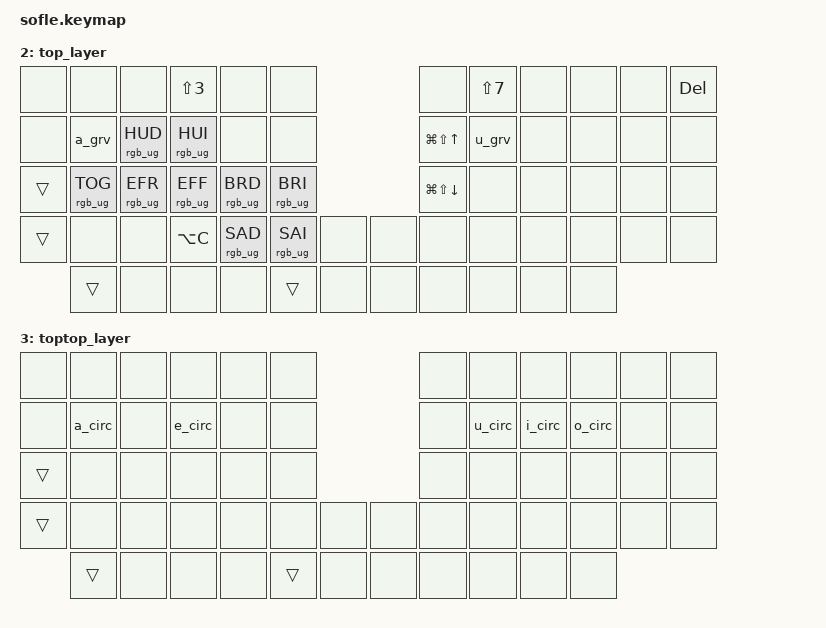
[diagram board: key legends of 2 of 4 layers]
/*
 * Copyright (c) 2020 The ZMK Contributors
 *
 * SPDX-License-Identifier: MIT
 */

#include <behaviors.dtsi>
#include <dt-bindings/zmk/keys.h>
#include <dt-bindings/zmk/bt.h>
#include <dt-bindings/zmk/ext_power.h>
#include <dt-bindings/zmk/rgb.h>


/ {

    chosen {
      zmk,battery = &vbatt;
    };

    vbatt: vbatt {
        compatible = "zmk,battery-nrf-vddh";
        label = "VBATT";
    };
    

    
    macros {
    
    layer_s: layer_s {
	    label = "layer shift color";
	    compatible = "zmk,behavior-macro";
	    #binding-cells = <0>;
	    wait-ms = <0>;
	    tap-ms = <0>;
	    bindings
		= <&macro_press &kp LSHFT>
		, <&macro_tap &rgb_ug RGB_COLOR_HSB(35,100,4)>
		, <&macro_pause_for_release>
		, <&macro_release &kp LSHFT>
		, <&macro_tap &rgb_ug RGB_COLOR_HSB(240,0,1)>
		;
	};
    

    layer_a: layer_a {
	    label = "layer a";
	    compatible = "zmk,behavior-macro";
	    #binding-cells = <0>;
	    wait-ms = <0>;
	    tap-ms = <0>;
	    bindings
		= <&macro_press &mo 1>
		, <&macro_tap &rgb_ug RGB_COLOR_HSB(300,100,4)>
		, <&macro_pause_for_release>
		, <&macro_release &mo 1>
		, <&macro_tap &rgb_ug RGB_COLOR_HSB(240,0,1)>
		;
	};
	
	layer_b: layer_b {
	    label = "layer b";
	    compatible = "zmk,behavior-macro";
	    #binding-cells = <0>;
	    wait-ms = <0>;
	    tap-ms = <0>;
	    bindings
		= <&macro_press &mo 2>
		, <&macro_tap &rgb_ug RGB_COLOR_HSB(175,100,4)>
		, <&macro_pause_for_release>
		, <&macro_release &mo 2>
		, <&macro_tap &rgb_ug RGB_COLOR_HSB(240,0,1)>
		;
	};
	
	layer_c: layer_c {
	    label = "layer c";
	    compatible = "zmk,behavior-macro";
	    #binding-cells = <0>;
	    wait-ms = <0>;
	    tap-ms = <0>;
	    bindings
		= <&macro_press &sl 3>
		, <&macro_tap &rgb_ug RGB_COLOR_HSB(0,100,4)>
		, <&macro_pause_for_release>
		, <&macro_release &sl 3>
		;
	};

        e_aig: e_aig {
            label = "e aigu";
	    tap-ms = <50>;
            compatible = "zmk,behavior-macro";
            #binding-cells = <0>;
            bindings
                = <&macro_tap &kp LA(E)>
                , <&macro_tap &kp E>
                ;
        };
	
	a_grv: a_grv {
            label = "a grave";
	    tap-ms = <50>;
            compatible = "zmk,behavior-macro";
            #binding-cells = <0>;
            bindings
                = <&macro_tap &kp LA(GRAVE)>
                , <&macro_tap &kp A>
                ;
        };
	
	a_circ: a_circ {
            label = "a circ";
	    tap-ms = <50>;
            compatible = "zmk,behavior-macro";
            #binding-cells = <0>;
            bindings
                = <&macro_tap &kp LA(I)>
                , <&macro_tap &kp A>
                ;
        };
	
	e_grv: e_grv {
            label = "e grave";
	    tap-ms = <50>;
            compatible = "zmk,behavior-macro";
            #binding-cells = <0>;
            bindings
                = <&macro_tap &kp LA(GRAVE)>
                , <&macro_tap &kp E>
                ;
        };
	
	e_circ: e_circ {
            label = "e circ";
	    tap-ms = <50>;
            compatible = "zmk,behavior-macro";
            #binding-cells = <0>;
            bindings
                = <&macro_tap &kp LA(I)>
                , <&macro_tap &kp E>
                ;
        };
	
	u_grv: u_grv {
            label = "u grave";
	    tap-ms = <50>;
            compatible = "zmk,behavior-macro";
            #binding-cells = <0>;
            bindings
                = <&macro_tap &kp LA(GRAVE)>
                , <&macro_tap &kp U>
                ;
        };
	
	u_circ: u_circ {
            label = "u circ";
	    tap-ms = <50>;
            compatible = "zmk,behavior-macro";
            #binding-cells = <0>;
            bindings
                = <&macro_tap &kp LA(I)>
                , <&macro_tap &kp U>
                ;
        };
	
	o_circ: o_circ {
            label = "o circ";
	    tap-ms = <50>;
            compatible = "zmk,behavior-macro";
            #binding-cells = <0>;
            bindings
                = <&macro_tap &kp LA(I)>
                , <&macro_tap &kp O>
                ;
        };
	
	i_circ: i_circ {
            label = "i circ";
	    tap-ms = <50>;
            compatible = "zmk,behavior-macro";
            #binding-cells = <0>;
            bindings
                = <&macro_tap &kp LA(I)>
                , <&macro_tap &kp I>
                ;
        };

    };

    behaviors {
        hm: homerow_mods {
            compatible = "zmk,behavior-hold-tap";
            label = "HOMEROW_MODS";
            #binding-cells = <2>;
            tapping-term-ms = <150>;
            quick-tap-ms = <0>;
            flavor = "tap-preferred";
            bindings = <&kp>, <&kp>;
        };

	aa: aa {
            compatible = "zmk,behavior-tap-dance";
            label = "select all";
            #binding-cells = <0>;
            tapping-term-ms = <100>;
            bindings = <&kp A>, <&kp LG(A)>;
        };

        cc: cc {
            compatible = "zmk,behavior-tap-dance";
            label = "copy";
            #binding-cells = <0>;
            tapping-term-ms = <100>;
            bindings = <&kp C>, <&kp LG(C)>;
        };

        cv: cv {
            compatible = "zmk,behavior-tap-dance";
            label = "paste";
            #binding-cells = <0>;
            tapping-term-ms = <100>;
            bindings = <&kp V>, <&kp LG(V)>;
        };

        cx: cx {
            compatible = "zmk,behavior-tap-dance";
            label = "cut";
            #binding-cells = <0>;
            tapping-term-ms = <100>;
            bindings = <&kp X>, <&kp LG(X)>;
        };
	
    };

	keymap {
		compatible = "zmk,keymap";

		default_layer {
// ------------------------------------------------------------------------------------------------------------
// |  ESC  |  1 ou !  | 2 ou é  | 3 ou #   | 4 ou $   | 5 ou %   |                 | 6 ou ^   | 7 ou é    | 8 ou *    | 9 ou (   |  0 ou )   | BACKSPACE |
// |  TAB  |  A       |  Z      |  E       |  R       |  T       |                 |  Y       |  U        |  I        |  O       |   P       |   + ou =  |
// |  CTRL |  Q       |  S      |  D       |  F       |  G       |                 |  H       |  J        |  K        |  L       |   M       |   ' ou "  |
// |  CMD  |  W       |  X      |  C       |  V       |  B       |  L/R  | | U/D   |  N       | ; ou :    |  , ou <   | . ou >   |   / ou ?  |  RIGHT    |
//                    | ALT     | [ ou {   | LOWER    |  SHIFT   | ENTER | | SPACE | UPPER    | - ou _    | }         |   LEFT   |
			bindings = <
    &kp ESC   &kp LS(N1) &e_aig      &kp LS(N3)        &kp LS(N4) &kp LS(N5)                        &kp LS(N6) &e_grv     &kp LS(N8)        &kp LS(N9)    &kp LS(N0)      &kp BSPC
    &kp TAB   &kp A      &kp Z       &kp E             &kp R      &kp T                             &kp Y      &kp U      &kp I             &kp O         &kp P           &kp EQUAL
    &kp LCTRL &kp Q      &kp S       &kp D             &kp F      &kp G                             &kp H      &kp J      &kp K             &kp L         &kp M           &kp SQT
    &kp LCMD  &kp W      &kp X       &kp C             &kp V      &kp B       &none     &none       &kp N      &kp SEMI   &kp COMMA         &kp DOT       &kp SLASH       &kp RIGHT
                         &kp LALT    &kp LBKT          &layer_a   &layer_s    &kp ENTER &kp SPACE   &layer_b   &kp MINUS  &kp RBKT          &kp LEFT
			>;
			
			sensor-bindings = <&inc_dec_kp LEFT RIGHT &inc_dec_kp DOWN UP>;

		};

		lower_layer {
// ------------------------------------------------------------------------------------------------------------
// | ESC    |  1  |   2    |   3     |  `     |  [          |                   |  F6        |  F7   |  F8              |   F9        |  F10      |  ]        |
// | BT_NXT | @   |        |         | rename |             |                   |            |  UP   | chrome dev tools | format code | = et +    | - et _    |
// |        |     |        |         |  find  | multi caret |                   | LEFT       | DOWN  |  RIGHT           |  "|"        | x meth    | $ et *    |
// |        |     | x meth | x const | x var  | x field     |        |  | del   | open class |       |                  |  \          |   line up | line down |
//                |        |    [    |        |             |        |  |       |            | ]     |            HOME  |  END        |
			bindings = <
&kp ESC              &kp N1             &kp N2          &kp N3              &kp N4          &kp N5                                        &kp N6      &kp N7           &kp N8           &kp N9           &kp N0           &kp DELETE
&bt BT_NXT           &kp LS(N2)         &none           &none               &kp LS(F6)      &none                                         &kp UP      &u_grv           &kp LA(LG(I))    &kp LA(LG(L))    &none            &trans
&trans               &none              &none           &none               &kp LC(LS(F))   &kp LC(LG(G))                                 &kp DOWN    &none            &none            &kp PIPE         &kp LA(LG(M))    &kp GRAVE
&trans               &none              &kp LA(LG(M))   &kp LA(LG(C))       &kp LA(LG(V))   &kp LA(LG(F))    &none         &none          &kp LG(N)   &none            &trans           &trans           &kp BACKSLASH    &kp TILDE
                                        &trans          &bt BT_CLR          &none           &trans            &kp LG(LEFT)  &kp LG(RIGHT)  &layer_c    &trans           &none            &none         
			>;

			sensor-bindings = <&inc_dec_kp BSPC DEL &inc_dec_kp PG_UP PG_DN>;
		};

        top_layer {
        // ------------------------------------------------------------------------------------------------------------
        // |       |F1   |  F2 |  F3  |  F4  |  F5   |                   |      |       |       |      |       |       |
        // |  >    |     |     |      |      |       |                   |      |       |       |      |       |       |
        // |       |     |     |      |      |       |                   |      |       |       |      |       |       |
        // |       |     |     |      |      |       |        |  |   <   |      |       |       |      |       |       |
        //               |     |      |      |       |        |  |       |      |       |       |      |
                    bindings = <
        &none                 &none           &none           &kp LS(N3)      &none           &none                                      &none               &kp LS(N7)       &none           &none     &none           &kp DELETE
        &none                 &a_grv          &rgb_ug RGB_HUD &rgb_ug RGB_HUI &none           &none                                      &kp LG(LS(UP))      &u_grv           &none           &none     &none           &none
        &trans                &rgb_ug RGB_TOG &rgb_ug RGB_EFR &rgb_ug RGB_EFF &rgb_ug RGB_BRD &rgb_ug RGB_BRI                            &kp LG(LS(DOWN))    &none            &none           &none     &none           &none
        &trans                &none           &none           &kp LA(C)       &rgb_ug RGB_SAD &rgb_ug RGB_SAI       &none    &none       &none               &none            &none           &none     &none           &none
                              &trans          &none           &none           &none           &trans                &none    &none       &none               &none            &none           &none
                    >;

			sensor-bindings = <&inc_dec_kp LA(LG(RIGHT)) LA(LG(LEFT))>;
                };
		
		toptop_layer {
        // ------------------------------------------------------------------------------------------------------------
        // |       |F1   |  F2 |  F3  |  F4  |  F5   |                   |      |       |       |      |       |       |
        // |  >    |     |     |      |      |       |                   |      |       |       |      |       |       |
        // |       |     |     |      |      |       |                   |      |       |       |      |       |       |
        // |       |     |     |      |      |       |        |  |   <   |      |       |       |      |       |       |
        //               |     |      |      |       |        |  |       |      |       |       |      |
                    bindings = <
        &none                 &none           &none           &none           &none           &none                                      &none               &none            &none           &none     &none           &none
        &none                 &a_circ         &none           &e_circ         &none           &none                                      &none               &u_circ          &i_circ         &o_circ   &none           &none
        &trans                &none           &none           &none           &none           &none                                      &none               &none            &none           &none     &none           &none
        &trans                &none           &none           &none           &none           &none                 &none    &none       &none               &none            &none           &none     &none           &none
                              &trans          &none           &none           &none           &trans                &none    &none       &none               &none            &none           &none
                    >;

                };



	};
};
